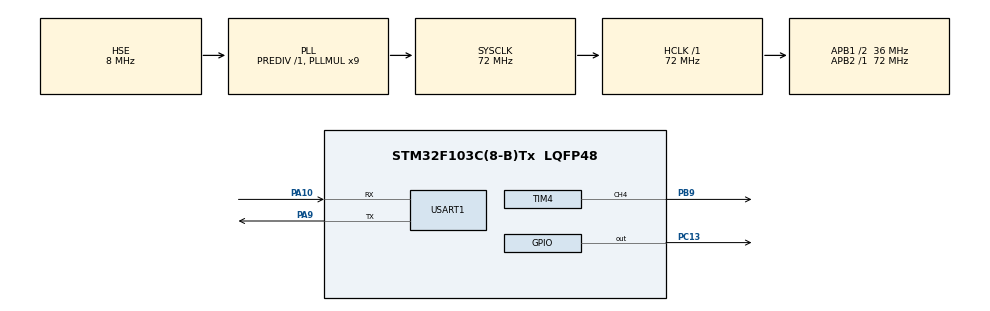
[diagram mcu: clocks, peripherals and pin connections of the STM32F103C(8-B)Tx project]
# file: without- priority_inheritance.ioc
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FREERTOS.BinarySemaphores01=feedbacksem,Dynamic,NULL,Available
FREERTOS.Mutexes01=uartmutex,Dynamic,NULL,Available
FREERTOS.Tasks01=defaultTask,0,128,StartDefaultTask,Default,NULL,Dynamic,NULL,NULL;myTask01,0,128,input_data,Default,NULL,Dynamic,NULL,NULL;myTask02,2,128,servo_cotrol,Default,NULL,Dynamic,NULL,NULL;myTask03,-2,128,feedback,Default,NULL,Dynamic,NULL,NULL
Mcu.Family=STM32F1
Mcu.Name=STM32F103C(8-B)Tx
Mcu.Package=LQFP48
NVIC.PriorityGroup=NVIC_PRIORITYGROUP_4
NVIC.TIM1_UP_IRQn=true\:15\:0\:false\:false\:true\:false\:false\:true\:true
NVIC.TimeBase=TIM1_UP_IRQn
NVIC.TimeBaseIP=TIM1
PA10.Mode=Asynchronous
PA10.Signal=USART1_RX
PA9.Mode=Asynchronous
PA9.Signal=USART1_TX
PB9.Signal=S_TIM4_CH4
PC13-TAMPER-RTC.Signal=GPIO_Output
PD0-OSC_IN.Mode=HSE-External-Oscillator
PD0-OSC_IN.Signal=RCC_OSC_IN
PD1-OSC_OUT.Mode=HSE-External-Oscillator
PD1-OSC_OUT.Signal=RCC_OSC_OUT
ProjectManager.HeapSize=0x200
ProjectManager.StackSize=0x400
ProjectManager.TargetToolchain=STM32CubeIDE
RCC.AHBFreq_Value=72000000
RCC.APB1CLKDivider=RCC_HCLK_DIV2
RCC.APB1Freq_Value=36000000
RCC.APB1TimFreq_Value=72000000
RCC.APB2Freq_Value=72000000
RCC.APB2TimFreq_Value=72000000
RCC.HCLKFreq_Value=72000000
RCC.PLLMUL=RCC_PLL_MUL9
RCC.PLLSourceVirtual=RCC_PLLSOURCE_HSE
RCC.SYSCLKFreq_VALUE=72000000
RCC.SYSCLKSource=RCC_SYSCLKSOURCE_PLLCLK
RCC.USBFreq_Value=72000000
SH.S_TIM4_CH4.0=TIM4_CH4,PWM Generation4 CH4
TIM4.Channel-PWM\ Generation4\ CH4=TIM_CHANNEL_4
TIM4.Period=19999
TIM4.Prescaler=71
USART1.VirtualMode=VM_ASYNC
VP_FREERTOS_VS_CMSIS_V1.Mode=CMSIS_V1
VP_SYS_VS_ND.Mode=No_Debug
VP_SYS_VS_tim1.Mode=TIM1
VP_TIM4_VS_ClockSourceINT.Mode=Internal
board=custom

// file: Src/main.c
/* USER CODE BEGIN Header */
/**
  ******************************************************************************
  * @file           : main.c
  * @brief          : Main program body
  ******************************************************************************
  * @attention
  *
  * Copyright (c) 2026 STMicroelectronics.
  * All rights reserved.
  *
  * This software is licensed under terms that can be found in the LICENSE file
  * in the root directory of this software component.
  * If no LICENSE file comes with this software, it is provided AS-IS.
  *
  ******************************************************************************
  */
/* USER CODE END Header */
#include "main.h"
#include "cmsis_os.h"

TIM_HandleTypeDef htim4;

UART_HandleTypeDef huart1;

osThreadId defaultTaskHandle;
osThreadId myTask01Handle;
osThreadId myTask02Handle;
osThreadId myTask03Handle;
osMutexId uartmutexHandle;
osSemaphoreId feedbacksemHandle;

void SystemClock_Config(void);
static void MX_GPIO_Init(void);
static void MX_USART1_UART_Init(void);
static void MX_TIM4_Init(void);
void StartDefaultTask(void const * argument);
void input_data(void const * argument);
void servo_cotrol(void const * argument);
void feedback(void const * argument);

/* USER CODE BEGIN 0 */
int last =0;

/* USER CODE END 0 */

int main(void)
{

  /* MCU Configuration--------------------------------------------------------*/

  /* Reset of all peripherals, Initializes the Flash interface and the Systick. */
  HAL_Init();

  /* Configure the system clock */
  SystemClock_Config();

  /* Initialize all configured peripherals */
  MX_GPIO_Init();
  MX_USART1_UART_Init();
  MX_TIM4_Init();

  /* Create the mutex(es) */
  /* definition and creation of uartmutex */
  osMutexDef(uartmutex);
  uartmutexHandle = osMutexCreate(osMutex(uartmutex));

  /* Create the semaphores(s) */
  /* definition and creation of feedbacksem */
  osSemaphoreDef(feedbacksem);
  feedbacksemHandle = osSemaphoreCreate(osSemaphore(feedbacksem), 1);

  /* Create the thread(s) */
  /* definition and creation of defaultTask */
  osThreadDef(defaultTask, StartDefaultTask, osPriorityNormal, 0, 128);
  defaultTaskHandle = osThreadCreate(osThread(defaultTask), NULL);

  /* definition and creation of myTask01 */
  osThreadDef(myTask01, input_data, osPriorityNormal, 0, 128);
  myTask01Handle = osThreadCreate(osThread(myTask01), NULL);

  /* definition and creation of myTask02 */
  osThreadDef(myTask02, servo_cotrol, osPriorityHigh, 0, 128);
  myTask02Handle = osThreadCreate(osThread(myTask02), NULL);

  /* definition and creation of myTask03 */
  osThreadDef(myTask03, feedback, osPriorityLow, 0, 128);
  myTask03Handle = osThreadCreate(osThread(myTask03), NULL);

  /* Start scheduler */
  osKernelStart();

  /* We should never get here as control is now taken by the scheduler */

  /* Infinite loop */
  while (1)
  {

    /* USER CODE BEGIN 3 */
	  if(HAL_GetTick()-last>=500){
		  HAL_GPIO_TogglePin(GPIOC, GPIO_PIN_13);
		 last= HAL_GetTick();
	  }
  }
  /* USER CODE END 3 */
}

void SystemClock_Config(void)
{
  RCC_OscInitTypeDef RCC_OscInitStruct = {0};
  RCC_ClkInitTypeDef RCC_ClkInitStruct = {0};

  /** Initializes the RCC Oscillators according to the specified parameters
  * in the RCC_OscInitTypeDef structure.
  */
  RCC_OscInitStruct.OscillatorType = RCC_OSCILLATORTYPE_HSE;
  RCC_OscInitStruct.HSEState = RCC_HSE_ON;
  RCC_OscInitStruct.HSEPredivValue = RCC_HSE_PREDIV_DIV1;
  RCC_OscInitStruct.HSIState = RCC_HSI_ON;
  RCC_OscInitStruct.PLL.PLLState = RCC_PLL_ON;
  RCC_OscInitStruct.PLL.PLLSource = RCC_PLLSOURCE_HSE;
  RCC_OscInitStruct.PLL.PLLMUL = RCC_PLL_MUL9;
  if (HAL_RCC_OscConfig(&RCC_OscInitStruct) != HAL_OK)
  {
    Error_Handler();
  }

  /** Initializes the CPU, AHB and APB buses clocks
  */
  RCC_ClkInitStruct.ClockType = RCC_CLOCKTYPE_HCLK|RCC_CLOCKTYPE_SYSCLK
                              |RCC_CLOCKTYPE_PCLK1|RCC_CLOCKTYPE_PCLK2;
  RCC_ClkInitStruct.SYSCLKSource = RCC_SYSCLKSOURCE_PLLCLK;
  RCC_ClkInitStruct.AHBCLKDivider = RCC_SYSCLK_DIV1;
  RCC_ClkInitStruct.APB1CLKDivider = RCC_HCLK_DIV2;
  RCC_ClkInitStruct.APB2CLKDivider = RCC_HCLK_DIV1;

  if (HAL_RCC_ClockConfig(&RCC_ClkInitStruct, FLASH_LATENCY_2) != HAL_OK)
  {
    Error_Handler();
  }
}

static void MX_TIM4_Init(void)
{

  TIM_ClockConfigTypeDef sClockSourceConfig = {0};
  TIM_MasterConfigTypeDef sMasterConfig = {0};
  TIM_OC_InitTypeDef sConfigOC = {0};

  htim4.Instance = TIM4;
  htim4.Init.Prescaler = 71;
  htim4.Init.CounterMode = TIM_COUNTERMODE_UP;
  htim4.Init.Period = 19999;
  htim4.Init.ClockDivision = TIM_CLOCKDIVISION_DIV1;
  htim4.Init.AutoReloadPreload = TIM_AUTORELOAD_PRELOAD_DISABLE;
  if (HAL_TIM_Base_Init(&htim4) != HAL_OK)
  {
    Error_Handler();
  }
  sClockSourceConfig.ClockSource = TIM_CLOCKSOURCE_INTERNAL;
  if (HAL_TIM_ConfigClockSource(&htim4, &sClockSourceConfig) != HAL_OK)
  {
    Error_Handler();
  }
  if (HAL_TIM_PWM_Init(&htim4) != HAL_OK)
  {
    Error_Handler();
  }
  sMasterConfig.MasterOutputTrigger = TIM_TRGO_RESET;
  sMasterConfig.MasterSlaveMode = TIM_MASTERSLAVEMODE_DISABLE;
  if (HAL_TIMEx_MasterConfigSynchronization(&htim4, &sMasterConfig) != HAL_OK)
  {
    Error_Handler();
  }
  sConfigOC.OCMode = TIM_OCMODE_PWM1;
  sConfigOC.Pulse = 0;
  sConfigOC.OCPolarity = TIM_OCPOLARITY_HIGH;
  sConfigOC.OCFastMode = TIM_OCFAST_DISABLE;
  if (HAL_TIM_PWM_ConfigChannel(&htim4, &sConfigOC, TIM_CHANNEL_4) != HAL_OK)
  {
    Error_Handler();
  }
  HAL_TIM_MspPostInit(&htim4);

}

static void MX_USART1_UART_Init(void)
{

  huart1.Instance = USART1;
  huart1.Init.BaudRate = 115200;
  huart1.Init.WordLength = UART_WORDLENGTH_8B;
  huart1.Init.StopBits = UART_STOPBITS_1;
  huart1.Init.Parity = UART_PARITY_NONE;
  huart1.Init.Mode = UART_MODE_TX_RX;
  huart1.Init.HwFlowCtl = UART_HWCONTROL_NONE;
  huart1.Init.OverSampling = UART_OVERSAMPLING_16;
  if (HAL_UART_Init(&huart1) != HAL_OK)
  {
    Error_Handler();
  }

}

static void MX_GPIO_Init(void)
{
  GPIO_InitTypeDef GPIO_InitStruct = {0};

  /* GPIO Ports Clock Enable */
  __HAL_RCC_GPIOC_CLK_ENABLE();
  __HAL_RCC_GPIOD_CLK_ENABLE();
  __HAL_RCC_GPIOA_CLK_ENABLE();
  __HAL_RCC_GPIOB_CLK_ENABLE();

  /*Configure GPIO pin Output Level */
  HAL_GPIO_WritePin(GPIOC, GPIO_PIN_13, GPIO_PIN_RESET);

  /*Configure GPIO pin : PC13 */
  GPIO_InitStruct.Pin = GPIO_PIN_13;
  GPIO_InitStruct.Mode = GPIO_MODE_OUTPUT_PP;
  GPIO_InitStruct.Pull = GPIO_NOPULL;
  GPIO_InitStruct.Speed = GPIO_SPEED_FREQ_LOW;
  HAL_GPIO_Init(GPIOC, &GPIO_InitStruct);

}

void StartDefaultTask(void const * argument)
{
  /* USER CODE BEGIN 5 */
	  int last =0;

  /* Infinite loop */
  for(;;)
  {
	  if(HAL_GetTick()-last>=500){
	 		  HAL_GPIO_TogglePin(GPIOC, GPIO_PIN_13);
	 		 last= HAL_GetTick();  }
  /* USER CODE END 5 */
}
}

void input_data(void const * argument)
{
  for(;;)
  {
    osDelay(1);
  }
}

void servo_cotrol(void const * argument)
{
  for(;;)
  {
    osDelay(1);
  }
}

void feedback(void const * argument)
{
  for(;;)
  {
    osDelay(1);
  }
}

void HAL_TIM_PeriodElapsedCallback(TIM_HandleTypeDef *htim)
{
  if (htim->Instance == TIM1)
  {
    HAL_IncTick();
  }
}

void Error_Handler(void)
{
  __disable_irq();
  while (1)
  {
  }
}
